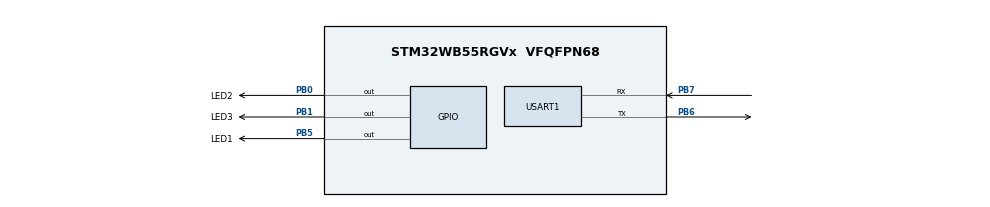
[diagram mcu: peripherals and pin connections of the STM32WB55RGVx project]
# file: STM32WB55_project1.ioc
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Mcu.Family=STM32WB
Mcu.Name=STM32WB55RGVx
Mcu.Package=VFQFPN68
NVIC.PriorityGroup=NVIC_PRIORITYGROUP_4
PB0.GPIO_Label=LED2
PB0.Signal=GPIO_Output
PB1.GPIO_Label=LED3
PB1.Signal=GPIO_Output
PB5.GPIO_Label=LED1
PB5.Signal=GPIO_Output
PB6.Mode=Asynchronous
PB6.Signal=USART1_TX
PB7.Mode=Asynchronous
PB7.Signal=USART1_RX
ProjectManager.HeapSize=0x2000
ProjectManager.StackSize=0x4000
ProjectManager.TargetToolchain=MDK-ARM V5.32
RCC.ADCFreq_Value=16000000
RCC.AHB2CLKDivider=RCC_SYSCLK_DIV2
RCC.AHBFreq_Value=64000000
RCC.APB1Freq_Value=64000000
RCC.APB1TimFreq_Value=64000000
RCC.APB2Freq_Value=64000000
RCC.APB2TimFreq_Value=64000000
RCC.APB3Freq_Value=16000000
RCC.Cortex2_Div=SYSTICK_CLKSOURCE_HCLK_DIV8
RCC.CortexFreq_Value=64000000
RCC.HCLKFreq_Value=64000000
RCC.HSE_VALUE=8000000
RCC.HSI48_VALUE=48000000
RCC.HSI_VALUE=16000000
RCC.LSE_VALUE=32768
RCC.PLLN=32
RCC.SYSCLKFreq_VALUE=64000000
RCC.SYSCLKSource=RCC_SYSCLKSOURCE_PLLCLK
RCC.USBFreq_Value=16000000
RCC.VCOOutputFreq_Value=128000000
USART1.VirtualMode-Asynchronous=VM_ASYNC
VP_MEMORYMAP_VS_MEMORYMAP.Mode=CurAppReg
board=custom

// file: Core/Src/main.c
/* USER CODE BEGIN Header */
/**
  ******************************************************************************
  * @file           : main.c
  * @brief          : Main program body
  ******************************************************************************
  * @attention
  *
  * Copyright (c) 2024 STMicroelectronics.
  * All rights reserved.
  *
  * This software is licensed under terms that can be found in the LICENSE file
  * in the root directory of this software component.
  * If no LICENSE file comes with this software, it is provided AS-IS.
  *
  ******************************************************************************
  */
/* USER CODE END Header */
#include "main.h"
#include "memorymap.h"
#include "usart.h"
#include "gpio.h"

/* USER CODE BEGIN Includes */
#include "stdio.h"
/* USER CODE END Includes */

void SystemClock_Config(void);
void PeriphCommonClock_Config(void);
/* USER CODE BEGIN PFP */
int fputc(int ch, FILE *f){
	HAL_UART_Transmit(&huart1 , (uint8_t *)&ch, 1, 0xFFFF);
	return ch;
}
/* USER CODE END PFP */

int main(void)
{

  /* MCU Configuration--------------------------------------------------------*/

  /* Reset of all peripherals, Initializes the Flash interface and the Systick. */
  HAL_Init();

  /* Configure the system clock */
  SystemClock_Config();

  /* Configure the peripherals common clocks */
  PeriphCommonClock_Config();

  /* Initialize all configured peripherals */
  MX_GPIO_Init();
  MX_USART1_UART_Init();

  /* Infinite loop */
  /* USER CODE BEGIN WHILE */
  while (1)
  {
		HAL_GPIO_WritePin(LED1_GPIO_Port, LED1_Pin, GPIO_PIN_SET);
		HAL_GPIO_WritePin(LED2_GPIO_Port, LED2_Pin, GPIO_PIN_SET);
		HAL_GPIO_WritePin(LED3_GPIO_Port, LED3_Pin, GPIO_PIN_SET);
		printf("LED ON!\n");
		HAL_Delay(1000);
		HAL_GPIO_WritePin(LED1_GPIO_Port, LED1_Pin, GPIO_PIN_RESET);
		HAL_GPIO_WritePin(LED2_GPIO_Port, LED2_Pin, GPIO_PIN_RESET);
		HAL_GPIO_WritePin(LED3_GPIO_Port, LED3_Pin, GPIO_PIN_RESET);
		printf("LED OFF!\n");
		HAL_Delay(1000);
    /* USER CODE END WHILE */

  }
}

void SystemClock_Config(void)
{
  RCC_OscInitTypeDef RCC_OscInitStruct = {0};
  RCC_ClkInitTypeDef RCC_ClkInitStruct = {0};

  /** Configure the main internal regulator output voltage
  */
  __HAL_PWR_VOLTAGESCALING_CONFIG(PWR_REGULATOR_VOLTAGE_SCALE1);

  /** Initializes the RCC Oscillators according to the specified parameters
  * in the RCC_OscInitTypeDef structure.
  */
  RCC_OscInitStruct.OscillatorType = RCC_OSCILLATORTYPE_HSI|RCC_OSCILLATORTYPE_MSI;
  RCC_OscInitStruct.HSIState = RCC_HSI_ON;
  RCC_OscInitStruct.MSIState = RCC_MSI_ON;
  RCC_OscInitStruct.HSICalibrationValue = RCC_HSICALIBRATION_DEFAULT;
  RCC_OscInitStruct.MSICalibrationValue = RCC_MSICALIBRATION_DEFAULT;
  RCC_OscInitStruct.MSIClockRange = RCC_MSIRANGE_6;
  RCC_OscInitStruct.PLL.PLLState = RCC_PLL_ON;
  RCC_OscInitStruct.PLL.PLLSource = RCC_PLLSOURCE_MSI;
  RCC_OscInitStruct.PLL.PLLM = RCC_PLLM_DIV1;
  RCC_OscInitStruct.PLL.PLLN = 32;
  RCC_OscInitStruct.PLL.PLLP = RCC_PLLP_DIV2;
  RCC_OscInitStruct.PLL.PLLR = RCC_PLLR_DIV2;
  RCC_OscInitStruct.PLL.PLLQ = RCC_PLLQ_DIV2;
  if (HAL_RCC_OscConfig(&RCC_OscInitStruct) != HAL_OK)
  {
    Error_Handler();
  }

  /** Configure the SYSCLKSource, HCLK, PCLK1 and PCLK2 clocks dividers
  */
  RCC_ClkInitStruct.ClockType = RCC_CLOCKTYPE_HCLK4|RCC_CLOCKTYPE_HCLK2
                              |RCC_CLOCKTYPE_HCLK|RCC_CLOCKTYPE_SYSCLK
                              |RCC_CLOCKTYPE_PCLK1|RCC_CLOCKTYPE_PCLK2;
  RCC_ClkInitStruct.SYSCLKSource = RCC_SYSCLKSOURCE_PLLCLK;
  RCC_ClkInitStruct.AHBCLKDivider = RCC_SYSCLK_DIV1;
  RCC_ClkInitStruct.APB1CLKDivider = RCC_HCLK_DIV1;
  RCC_ClkInitStruct.APB2CLKDivider = RCC_HCLK_DIV1;
  RCC_ClkInitStruct.AHBCLK2Divider = RCC_SYSCLK_DIV2;
  RCC_ClkInitStruct.AHBCLK4Divider = RCC_SYSCLK_DIV1;

  if (HAL_RCC_ClockConfig(&RCC_ClkInitStruct, FLASH_LATENCY_3) != HAL_OK)
  {
    Error_Handler();
  }
}

void PeriphCommonClock_Config(void)
{
  RCC_PeriphCLKInitTypeDef PeriphClkInitStruct = {0};

  /** Initializes the peripherals clock
  */
  PeriphClkInitStruct.PeriphClockSelection = RCC_PERIPHCLK_SMPS;
  PeriphClkInitStruct.SmpsClockSelection = RCC_SMPSCLKSOURCE_HSI;
  PeriphClkInitStruct.SmpsDivSelection = RCC_SMPSCLKDIV_RANGE1;

  if (HAL_RCCEx_PeriphCLKConfig(&PeriphClkInitStruct) != HAL_OK)
  {
    Error_Handler();
  }
}

void Error_Handler(void)
{
  __disable_irq();
  while (1)
  {
  }
}
